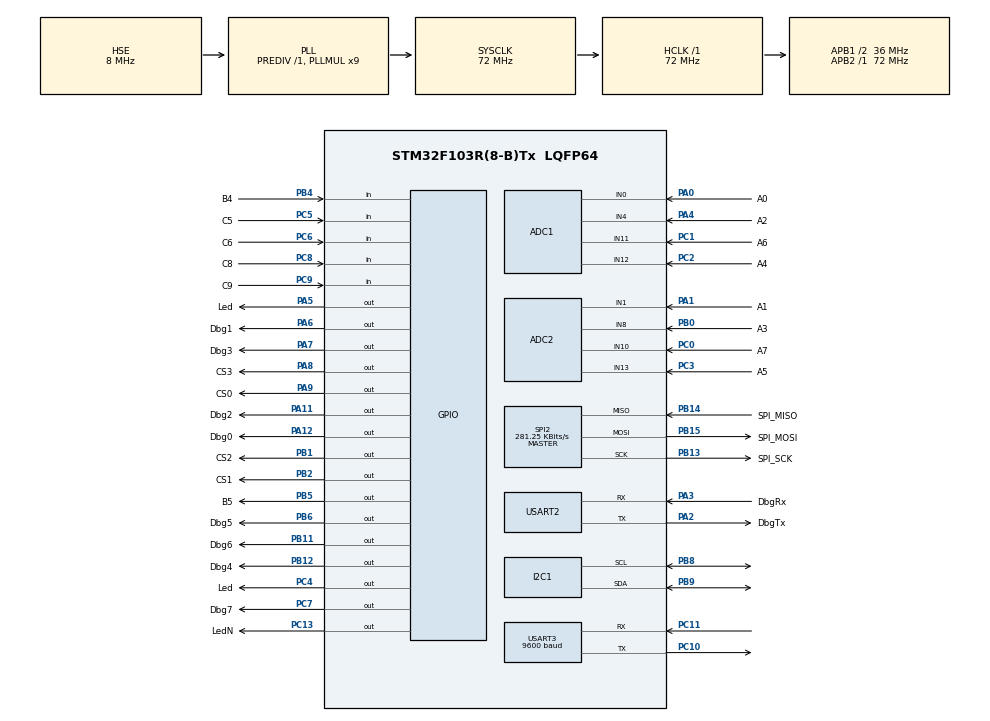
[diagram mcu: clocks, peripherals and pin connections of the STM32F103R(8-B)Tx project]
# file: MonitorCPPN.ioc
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ADC1.Channel-0\#ChannelRegularConversion=ADC_CHANNEL_0
ADC1.NbrOfConversion=1
ADC1.NbrOfConversionFlag=1
ADC1.Rank-0\#ChannelRegularConversion=1
ADC1.SamplingTime-0\#ChannelRegularConversion=ADC_SAMPLETIME_55CYCLES_5
ADC1.master=1
ADC2.Channel-0\#ChannelRegularConversion=ADC_CHANNEL_1
ADC2.NbrOfConversionFlag=1
ADC2.Rank-0\#ChannelRegularConversion=1
ADC2.SamplingTime-0\#ChannelRegularConversion=ADC_SAMPLETIME_55CYCLES_5
Mcu.Family=STM32F1
Mcu.Name=STM32F103R(8-B)Tx
Mcu.Package=LQFP64
NVIC.ADC1_2_IRQn=true\:0\:0\:false\:false\:false\:true\:false\:true
NVIC.PriorityGroup=NVIC_PRIORITYGROUP_4
NVIC.TIM1_UP_IRQn=true\:0\:0\:false\:false\:false\:true\:false\:true
PA0-WKUP.GPIO_Label=A0
PA0-WKUP.Signal=ADCx_IN0
PA1.GPIO_Label=A1
PA1.Signal=ADCx_IN1
PA11.GPIO_Label=Dbg2
PA11.Signal=GPIO_Output
PA12.GPIO_Label=Dbg0
PA12.Signal=GPIO_Output
PA13.GPIO_Label=TMS
PA13.Mode=Serial_Wire
PA13.Signal=SYS_JTMS-SWDIO
PA14.GPIO_Label=TCK
PA14.Mode=Serial_Wire
PA14.Signal=SYS_JTCK-SWCLK
PA2.GPIO_Label=DbgTx
PA2.GPIO_Mode=GPIO_MODE_AF_PP
PA2.GPIO_PuPd=GPIO_NOPULL
PA2.GPIO_Speed=GPIO_SPEED_FREQ_LOW
PA2.Mode=Asynchronous
PA2.Signal=USART2_TX
PA3.GPIO_Label=DbgRx
PA3.GPIO_Mode=GPIO_MODE_AF_PP
PA3.GPIO_PuPd=GPIO_NOPULL
PA3.GPIO_Speed=GPIO_SPEED_FREQ_LOW
PA3.Mode=Asynchronous
PA3.Signal=USART2_RX
PA4.GPIO_Label=A2
PA4.Signal=ADCx_IN4
PA5.GPIO_Label=Led
PA5.GPIO_ModeDefaultOutputPP=GPIO_MODE_OUTPUT_PP
PA5.GPIO_PuPd=GPIO_NOPULL
PA5.GPIO_Speed=GPIO_SPEED_FREQ_LOW
PA5.Signal=GPIO_Output
PA6.GPIO_Label=Dbg1
PA6.Signal=GPIO_Output
PA7.GPIO_Label=Dbg3
PA7.Signal=GPIO_Output
PA8.GPIO_Label=CS3
PA8.Signal=GPIO_Output
PA9.GPIO_Label=CS0
PA9.Signal=GPIO_Output
PB0.GPIO_Label=A3
PB0.Signal=ADCx_IN8
PB1.GPIO_Label=CS2
PB1.Signal=GPIO_Output
PB11.GPIO_Label=Dbg6
PB11.Signal=GPIO_Output
PB12.GPIO_Label=Dbg4
PB12.Signal=GPIO_Output
PB13.GPIO_Label=SPI_SCK
PB13.Mode=Full_Duplex_Master
PB13.Signal=SPI2_SCK
PB14.GPIO_Label=SPI_MISO
PB14.Mode=Full_Duplex_Master
PB14.Signal=SPI2_MISO
PB15.GPIO_Label=SPI_MOSI
PB15.Mode=Full_Duplex_Master
PB15.Signal=SPI2_MOSI
PB2.GPIO_Label=CS1
PB2.Signal=GPIO_Output
PB3.GPIO_Label=SWO
PB3.Signal=SYS_JTDO-TRACESWO
PB4.GPIO_Label=B4
PB4.Signal=GPIO_Input
PB5.GPIO_Label=B5
PB5.Signal=GPIO_Output
PB6.GPIO_Label=Dbg5
PB6.Signal=GPIO_Output
PB8.Mode=I2C
PB8.Signal=I2C1_SCL
PB9.Mode=I2C
PB9.Signal=I2C1_SDA
PC0.GPIO_Label=A7
PC0.Signal=ADCx_IN10
PC1.GPIO_Label=A6
PC1.Signal=ADCx_IN11
PC10.Mode=Asynchronous
PC10.Signal=USART3_TX
PC11.Mode=Asynchronous
PC11.Signal=USART3_RX
PC13-TAMPER-RTC.GPIO_Label=LedN
PC13-TAMPER-RTC.Signal=GPIO_Output
PC14-OSC32_IN.Mode=LSE-External-Oscillator
PC14-OSC32_IN.Signal=RCC_OSC32_IN
PC15-OSC32_OUT.Mode=LSE-External-Oscillator
PC15-OSC32_OUT.Signal=RCC_OSC32_OUT
PC2.GPIO_Label=A4
PC2.Signal=ADCx_IN12
PC3.GPIO_Label=A5
PC3.Signal=ADCx_IN13
PC4.GPIO_Label=Led
PC4.Signal=GPIO_Output
PC5.GPIO_Label=C5
PC5.Signal=GPIO_Input
PC6.GPIO_Label=C6
PC6.Signal=GPIO_Input
PC7.GPIO_Label=Dbg7
PC7.Signal=GPIO_Output
PC8.GPIO_Label=C8
PC8.Signal=GPIO_Input
PC9.GPIO_Label=C9
PC9.Signal=GPIO_Input
PD0-OSC_IN.Mode=HSE-External-Clock-Source
PD0-OSC_IN.Signal=RCC_OSC_IN
PD1-OSC_OUT.Mode=HSE-External-Clock-Source
PD1-OSC_OUT.Signal=RCC_OSC_OUT
ProjectManager.HeapSize=0x200
ProjectManager.StackSize=0x400
ProjectManager.TargetToolchain=STM32CubeIDE
RCC.ADCPresc=RCC_ADCPCLK2_DIV6
RCC.AHBFreq_Value=72000000
RCC.APB1CLKDivider=RCC_HCLK_DIV2
RCC.APB1Freq_Value=36000000
RCC.APB1TimFreq_Value=72000000
RCC.APB2Freq_Value=72000000
RCC.APB2TimFreq_Value=72000000
RCC.HCLKFreq_Value=72000000
RCC.PLLMUL=RCC_PLL_MUL9
RCC.PLLSourceVirtual=RCC_PLLSOURCE_HSE
RCC.RTCClockSelection=RCC_RTCCLKSOURCE_LSE
RCC.SYSCLKFreq_VALUE=72000000
RCC.SYSCLKSource=RCC_SYSCLKSOURCE_PLLCLK
RCC.USBFreq_Value=72000000
SH.ADCx_IN0.0=ADC1_IN0,IN0
SH.ADCx_IN1.0=ADC2_IN1,IN1
SH.ADCx_IN10.0=ADC2_IN10,IN10
SH.ADCx_IN11.0=ADC1_IN11,IN11
SH.ADCx_IN12.0=ADC1_IN12,IN12
SH.ADCx_IN13.0=ADC2_IN13,IN13
SH.ADCx_IN4.0=ADC1_IN4,IN4
SH.ADCx_IN8.0=ADC2_IN8,IN8
SPI2.BaudRatePrescaler=SPI_BAUDRATEPRESCALER_128
SPI2.CLKPhase=SPI_PHASE_2EDGE
SPI2.CLKPolarity=SPI_POLARITY_LOW
SPI2.CalculateBaudRate=281.25 KBits/s
SPI2.Direction=SPI_DIRECTION_2LINES
SPI2.Mode=SPI_MODE_MASTER
SPI2.VirtualType=VM_MASTER
TIM1.Channel-Output\ Compare1\ No\ Output=TIM_CHANNEL_1
TIM1.Period=60000-1
TIM1.Prescaler=2-1
USART2.VirtualMode=VM_ASYNC
USART3.BaudRate=9600
USART3.VirtualMode=VM_ASYNC
VP_RTC_VS_RTC_Activate.Mode=RTC_Enabled
VP_TIM1_VS_ClockSourceINT.Mode=Internal
VP_TIM1_VS_no_output1.Mode=Output Compare1 No Output
board=NUCLEO-F103RB

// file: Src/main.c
/* USER CODE BEGIN Header */
/**
  ******************************************************************************
  * @file           : main.c
  * @brief          : Main program body
  ******************************************************************************
  ** This notice applies to any and all portions of this file
  * that are not between comment pairs USER CODE BEGIN and
  * USER CODE END. Other portions of this file, whether
  * inserted by the user or by software development tools
  * are owned by their respective copyright owners.
  *
  * COPYRIGHT(c) 2018 STMicroelectronics
  *
  * Redistribution and use in source and binary forms, with or without modification,
  * are permitted provided that the following conditions are met:
  *   1. Redistributions of source code must retain the above copyright notice,
  *      this list of conditions and the following disclaimer.
  *   2. Redistributions in binary form must reproduce the above copyright notice,
  *      this list of conditions and the following disclaimer in the documentation
  *      and/or other materials provided with the distribution.
  *   3. Neither the name of STMicroelectronics nor the names of its contributors
  *      may be used to endorse or promote products derived from this software
  *      without specific prior written permission.
  *
  * THIS SOFTWARE IS PROVIDED BY THE COPYRIGHT HOLDERS AND CONTRIBUTORS "AS IS"
  * AND ANY EXPRESS OR IMPLIED WARRANTIES, INCLUDING, BUT NOT LIMITED TO, THE
  * IMPLIED WARRANTIES OF MERCHANTABILITY AND FITNESS FOR A PARTICULAR PURPOSE ARE
  * DISCLAIMED. IN NO EVENT SHALL THE COPYRIGHT HOLDER OR CONTRIBUTORS BE LIABLE
  * FOR ANY DIRECT, INDIRECT, INCIDENTAL, SPECIAL, EXEMPLARY, OR CONSEQUENTIAL
  * DAMAGES (INCLUDING, BUT NOT LIMITED TO, PROCUREMENT OF SUBSTITUTE GOODS OR
  * SERVICES; LOSS OF USE, DATA, OR PROFITS; OR BUSINESS INTERRUPTION) HOWEVER
  * CAUSED AND ON ANY THEORY OF LIABILITY, WHETHER IN CONTRACT, STRICT LIABILITY,
  * OR TORT (INCLUDING NEGLIGENCE OR OTHERWISE) ARISING IN ANY WAY OUT OF THE USE
  * OF THIS SOFTWARE, EVEN IF ADVISED OF THE POSSIBILITY OF SUCH DAMAGE.
  *
  ******************************************************************************
  */
/* USER CODE END Header */
#include "main.h"
#include "adc.h"
#include "i2c.h"
#include "rtc.h"
#include "spi.h"
#include "tim.h"
#include "usart.h"
#include "gpio.h"

/* USER CODE BEGIN Includes */
#include <stdio.h>
/* USER CODE END Includes */

/* USER CODE BEGIN PV */
/* Private variables ---------------------------------------------------------*/

/* USER CODE END PV */

void SystemClock_Config(void);

/* USER CODE BEGIN 0 */

void monitorLoop(void);

void _init(void);
caddr_t _sbrk(int incr);
void _close(void);
void _lseek(void);
int _isatty(void);
void _read(void);
int _fstat(void);

ssize_t _write (int fd, const char* buf, size_t nbyte);

/* USER CODE END 0 */

int main(void)
{

  /* MCU Configuration--------------------------------------------------------*/

  /* Reset of all peripherals, Initializes the Flash interface and the Systick. */
  HAL_Init();

  /* Configure the system clock */
  SystemClock_Config();

  /* Initialize all configured peripherals */
  MX_GPIO_Init();
  MX_ADC1_Init();
  MX_ADC2_Init();
  MX_RTC_Init();
  MX_TIM1_Init();
  MX_USART2_UART_Init();
  MX_USART3_UART_Init();
  MX_I2C1_Init();
  MX_SPI2_Init();
  /* USER CODE BEGIN 2 */

  monitorLoop();

  /* USER CODE END 2 */

  /* Infinite loop */
  while (1)
  {

  }
}

void SystemClock_Config(void)
{
  RCC_OscInitTypeDef RCC_OscInitStruct = {0};
  RCC_ClkInitTypeDef RCC_ClkInitStruct = {0};
  RCC_PeriphCLKInitTypeDef PeriphClkInit = {0};

  /** Initializes the RCC Oscillators according to the specified parameters
  * in the RCC_OscInitTypeDef structure.
  */
  RCC_OscInitStruct.OscillatorType = RCC_OSCILLATORTYPE_HSE|RCC_OSCILLATORTYPE_LSE;
  RCC_OscInitStruct.HSEState = RCC_HSE_BYPASS;
  RCC_OscInitStruct.HSEPredivValue = RCC_HSE_PREDIV_DIV1;
  RCC_OscInitStruct.LSEState = RCC_LSE_ON;
  RCC_OscInitStruct.HSIState = RCC_HSI_ON;
  RCC_OscInitStruct.PLL.PLLState = RCC_PLL_ON;
  RCC_OscInitStruct.PLL.PLLSource = RCC_PLLSOURCE_HSE;
  RCC_OscInitStruct.PLL.PLLMUL = RCC_PLL_MUL9;
  if (HAL_RCC_OscConfig(&RCC_OscInitStruct) != HAL_OK)
  {
    Error_Handler();
  }

  /** Initializes the CPU, AHB and APB buses clocks
  */
  RCC_ClkInitStruct.ClockType = RCC_CLOCKTYPE_HCLK|RCC_CLOCKTYPE_SYSCLK
                              |RCC_CLOCKTYPE_PCLK1|RCC_CLOCKTYPE_PCLK2;
  RCC_ClkInitStruct.SYSCLKSource = RCC_SYSCLKSOURCE_PLLCLK;
  RCC_ClkInitStruct.AHBCLKDivider = RCC_SYSCLK_DIV1;
  RCC_ClkInitStruct.APB1CLKDivider = RCC_HCLK_DIV2;
  RCC_ClkInitStruct.APB2CLKDivider = RCC_HCLK_DIV1;

  if (HAL_RCC_ClockConfig(&RCC_ClkInitStruct, FLASH_LATENCY_2) != HAL_OK)
  {
    Error_Handler();
  }
  PeriphClkInit.PeriphClockSelection = RCC_PERIPHCLK_RTC|RCC_PERIPHCLK_ADC;
  PeriphClkInit.RTCClockSelection = RCC_RTCCLKSOURCE_LSE;
  PeriphClkInit.AdcClockSelection = RCC_ADCPCLK2_DIV6;
  if (HAL_RCCEx_PeriphCLKConfig(&PeriphClkInit) != HAL_OK)
  {
    Error_Handler();
  }
}

void Error_Handler(void)
{
  while(1)
  {
  }
}

#ifdef  USE_FULL_ASSERT
/**
  * @brief  Reports the name of the source file and the source line number
  *         where the assert_param error has occurred.
  * @param  file: pointer to the source file name
  * @param  line: assert_param error line source number
  * @retval None
  */
void assert_failed(uint8_t *file, uint32_t line)
{
  /* USER CODE BEGIN 6 */
 printf("assert_failed %s line %ld\n", file, line);
  /* User can add his own implementation to report the file name and line number,
     tex: printf("Wrong parameters value: file %s on line %d\r\n", file, line) */
  /* USER CODE END 6 */
}
#endif /* USE_FULL_ASSERT */
